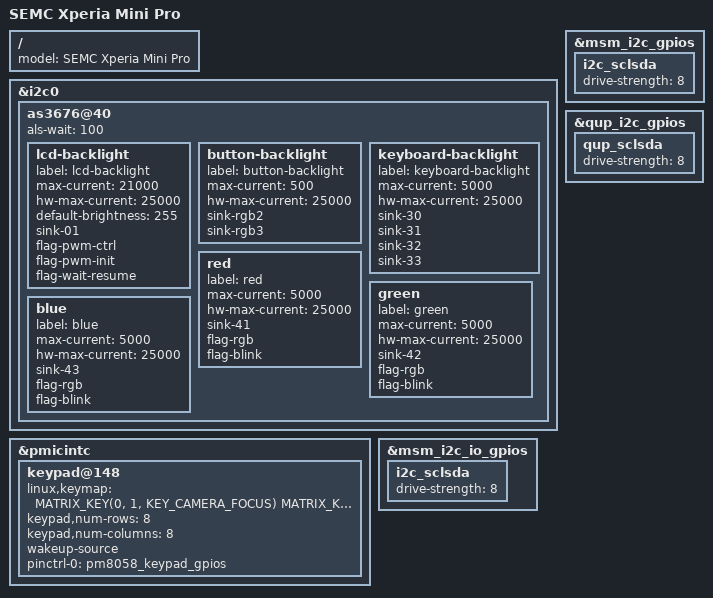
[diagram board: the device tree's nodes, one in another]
#include "qcom-msm7x30-semc-mogami.dtsi"

#include <dt-bindings/input/input.h>

/ {
	model = "SEMC Xperia Mini Pro";
};

&i2c0 {
	as3676@40 {
		als-wait = <100>;

		lcd-backlight {
			label = "lcd-backlight";
			max-current = <21000>;
			hw-max-current = <25000>;
			default-brightness = <255>;
			sink-01;
			flag-pwm-ctrl;
			flag-pwm-init;
			flag-wait-resume;
		};

		button-backlight {
			label = "button-backlight";
			max-current = <500>;
			hw-max-current = <25000>;
			sink-rgb2;
			sink-rgb3;
		};

		keyboard-backlight {
			label = "keyboard-backlight";
			max-current = <5000>;
			hw-max-current = <25000>;
			sink-30;
			sink-31;
			sink-32;
			sink-33;
		};

		red {
			label = "red";
			max-current = <5000>;
			hw-max-current = <25000>;
			sink-41;
			flag-rgb;
			flag-blink;
		};

		green {
			label = "green";
			max-current = <5000>;
			hw-max-current = <25000>;
			sink-42;
			flag-rgb;
			flag-blink;
		};

		blue {
			label = "blue";
			max-current = <5000>;
			hw-max-current = <25000>;
			sink-43;
			flag-rgb;
			flag-blink;
		};
	};
};

&pmicintc {
	keypad@148 {
		linux,keymap = <
			MATRIX_KEY(0, 1, KEY_CAMERA_FOCUS)
			MATRIX_KEY(0, 2, KEY_COMPOSE)
			MATRIX_KEY(0, 3, KEY_SPACE)
			MATRIX_KEY(0, 4, KEY_ENTER)
			MATRIX_KEY(0, 5, KEY_DOT)
			MATRIX_KEY(0, 6, KEY_UP)

			MATRIX_KEY(1, 0, KEY_HOME)
			MATRIX_KEY(1, 1, KEY_CAMERA)
			MATRIX_KEY(1, 3, KEY_A)
			MATRIX_KEY(1, 4, KEY_D)
			MATRIX_KEY(1, 5, KEY_APOSTROPHE)
			MATRIX_KEY(1, 6, KEY_DOWN)

			MATRIX_KEY(2, 1, KEY_VOLUMEDOWN)
			MATRIX_KEY(2, 3, KEY_B)
			MATRIX_KEY(2, 5, KEY_RIGHTBRACE)
			MATRIX_KEY(2, 7, KEY_RIGHT)

			MATRIX_KEY(3, 0, KEY_LEFTSHIFT)
			MATRIX_KEY(3, 1, KEY_VOLUMEUP)
			MATRIX_KEY(3, 2, KEY_F)
			MATRIX_KEY(3, 3, KEY_COMMA)
			MATRIX_KEY(3, 4, KEY_Z)
			MATRIX_KEY(3, 5, KEY_E)
			MATRIX_KEY(3, 7, KEY_LEFT)

			MATRIX_KEY(4, 1, KEY_Q)
			MATRIX_KEY(4, 3, KEY_R)
			MATRIX_KEY(4, 4, KEY_C)
			MATRIX_KEY(4, 5, KEY_T)
			MATRIX_KEY(4, 6, KEY_LEFTALT)
			MATRIX_KEY(4, 7, KEY_V)

			MATRIX_KEY(5, 1, KEY_G)
			MATRIX_KEY(5, 2, KEY_LEFTBRACE)
			MATRIX_KEY(5, 4, KEY_Y)
			MATRIX_KEY(5, 5, KEY_H)
			MATRIX_KEY(5, 6, KEY_LANGUAGE)
			MATRIX_KEY(5, 7, KEY_X)

			MATRIX_KEY(6, 1, KEY_U)
			MATRIX_KEY(6, 2, KEY_N)
			MATRIX_KEY(6, 3, KEY_J)
			MATRIX_KEY(6, 5, KEY_I)
			MATRIX_KEY(6, 6, KEY_K)
			MATRIX_KEY(6, 7, KEY_M)

			MATRIX_KEY(7, 0, KEY_W)
			MATRIX_KEY(7, 1, KEY_S)
			MATRIX_KEY(7, 2, KEY_O)
			MATRIX_KEY(7, 4, KEY_L)
			MATRIX_KEY(7, 6, KEY_BACKSPACE)
			MATRIX_KEY(7, 7, KEY_P)
			>;
		keypad,num-rows = <8>;
		keypad,num-columns = <8>;
		wakeup-source;

		pinctrl-names = "default";
		pinctrl-0 = <&pm8058_keypad_gpios>;
	};
};

&msm_i2c_gpios {
	i2c_sclsda {
		drive-strength = <8>;
	};
};

&msm_i2c_io_gpios {
	i2c_sclsda {
		drive-strength = <8>;
	};
};

&qup_i2c_gpios {
	qup_sclsda {
		drive-strength = <8>;
	};
};
